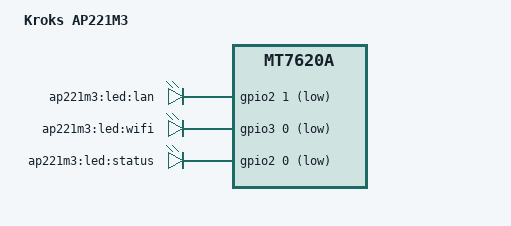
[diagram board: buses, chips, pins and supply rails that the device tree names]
#include "mt7620a_kroks_1eth-1mm.dtsi"

/ {
	compatible = "kroks,ap221m3", "ralink,mt7620a-soc";
	model = "Kroks AP221M3";

	aliases {
		led-boot = &led_status;
		led-failsafe = &led_status;
		led-running = &led_status;
		led-upgrade = &led_status;
	};

	leds {
		compatible = "gpio-leds";

		lan {
			label = "ap221m3:led:lan";
			gpios = <&gpio2 1 GPIO_ACTIVE_LOW>;
		};

		wifi {
			label = "ap221m3:led:wifi";
			gpios = <&gpio3 0 GPIO_ACTIVE_LOW>;
			linux,default-trigger = "phy0tpt";
		};

		led_status: status {
			label = "ap221m3:led:status";
			gpios = <&gpio2 0 GPIO_ACTIVE_LOW>;
		};
	};
};

&state_default {
	gpio_led {
		ralink,group = "ephy", "wled";
		ralink,function = "gpio";
	};
};
